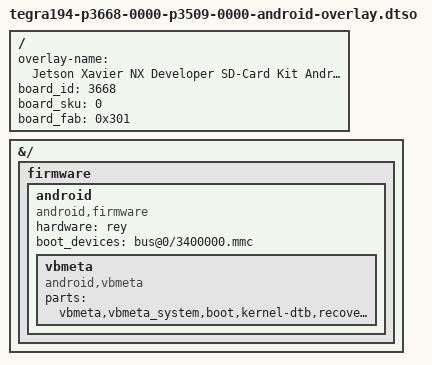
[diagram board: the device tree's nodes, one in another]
/dts-v1/;
/plugin/;

#include "tegra194-lineage.dtsi"

/ {
        overlay-name = "Jetson Xavier NX Developer SD-Card Kit Android Overlay";
        board_id = <3668>;
        board_sku = <0>;
        board_fab = <0x301>;
};

&{/} {
	firmware {
		android {
			compatible = "android,firmware";
			hardware = "rey";
			boot_devices = "bus@0/3400000.mmc";
			vbmeta {
				compatible = "android,vbmeta";
				parts = "vbmeta,vbmeta_system,boot,kernel-dtb,recovery";
			};
		};
	};
};
